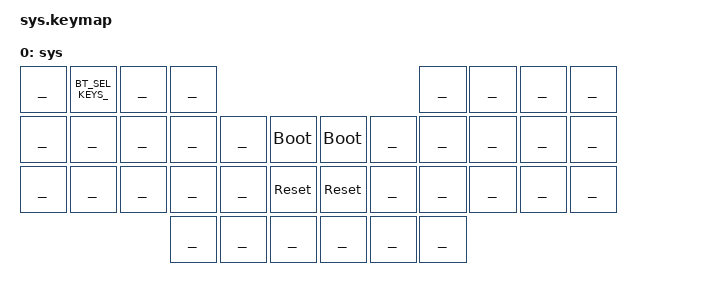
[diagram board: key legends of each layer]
ZMK_LAYER(sys,    // 4
//╭─────────────┬─────────────┬─────────────┬─────────────┬─────────────┬─────────────╮ ╭─────────────┬─────────────┬─────────────┬─────────────┬─────────────┬─────────────╮
    ___                                      _BT_SEL_KEYS_                                ___           ___           ___           ___           ___           ___
//├─────────────┼─────────────┼─────────────┼─────────────┼─────────────┼─────────────┤ ├─────────────┼─────────────┼─────────────┼─────────────┼─────────────┴─────────────┤
    ___           ___           ___           ___           ___           &bootloader     &bootloader   ___           ___           ___           ___           ___
//├─────────────┼─────────────┼─────────────┼─────────────┼─────────────┼─────────────┤ ├─────────────┼─────────────┼─────────────┼─────────────┼─────────────┴─────────────┤
    ___           ___           ___           ___           ___           &sys_reset      &sys_reset    ___           ___           ___           ___           ___
//╰─────────────┴─────────────┴─────────────┼─────────────┼─────────────┼─────────────┤ ├─────────────┼─────────────┼─────────────┼─────────────┴─────────────┴─────────────╯
                                              ___           ___           ___             ___           ___           ___ 
//                                          ╰─────────────┴─────────────┴─────────────╯ ╰─────────────┴─────────────┴─────────────╯
)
